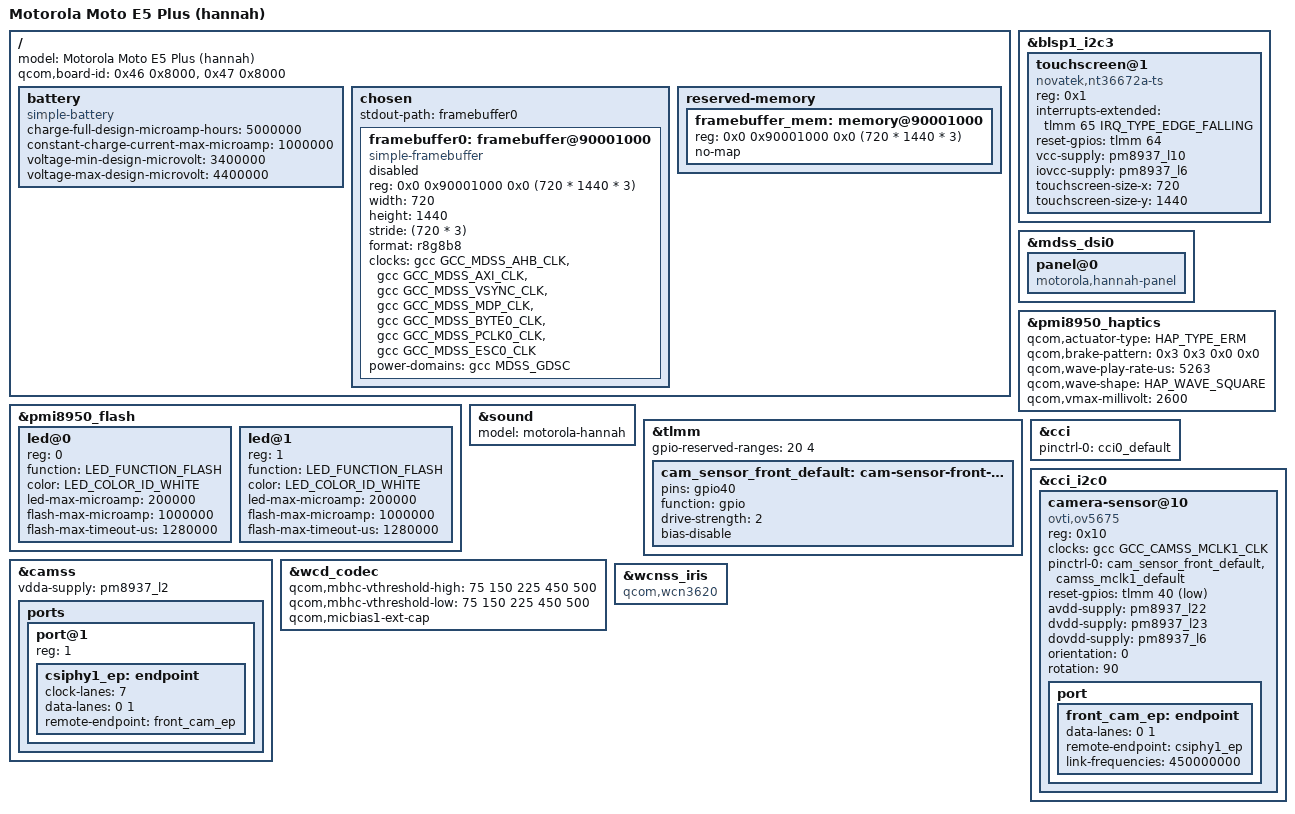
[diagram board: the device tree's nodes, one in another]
// SPDX-License-Identifier: BSD-3-Clause
/*
 * Copyright (c) 2025, Barnabas Czeman
 */

#include "msm89x7-motorola-common.dtsi"

/ {
	model = "Motorola Moto E5 Plus (hannah)";
	qcom,board-id = <0x46 0x8000>,
			<0x47 0x8000>;

	battery: battery {
		compatible = "simple-battery";

		charge-full-design-microamp-hours = <5000000>;
		constant-charge-current-max-microamp = <1000000>;
		voltage-min-design-microvolt = <3400000>;
		voltage-max-design-microvolt = <4400000>;
	};

	chosen {
		#address-cells = <2>;
		#size-cells = <2>;
		ranges;

		stdout-path = "framebuffer0";

		framebuffer0: framebuffer@90001000 {
			compatible = "simple-framebuffer";
			reg = <0x0 0x90001000 0x0 (720 * 1440 * 3)>;
			width = <720>;
			height = <1440>;
			stride = <(720 * 3)>;
			format = "r8g8b8";

			clocks = <&gcc GCC_MDSS_AHB_CLK>,
				 <&gcc GCC_MDSS_AXI_CLK>,
				 <&gcc GCC_MDSS_VSYNC_CLK>,
				 <&gcc GCC_MDSS_MDP_CLK>,
				 <&gcc GCC_MDSS_BYTE0_CLK>,
				 <&gcc GCC_MDSS_PCLK0_CLK>,
				 <&gcc GCC_MDSS_ESC0_CLK>;
			power-domains = <&gcc MDSS_GDSC>;
			status = "disabled";
		};
	};

	reserved-memory {
		framebuffer_mem: memory@90001000 {
			reg = <0x0 0x90001000 0x0 (720 * 1440 * 3)>;
			no-map;
		};
	};
};

&blsp1_i2c3 {
	status = "okay";

	touchscreen@1 {
		compatible = "novatek,nt36672a-ts";
		reg = <0x1>;
		interrupts-extended = <&tlmm 65 IRQ_TYPE_EDGE_FALLING>;
		reset-gpios = <&tlmm 64 GPIO_ACTIVE_HIGH>;
		vcc-supply = <&pm8937_l10>;
		iovcc-supply = <&pm8937_l6>;
		touchscreen-size-x = <720>;
		touchscreen-size-y = <1440>;
	};
};

&mdss_dsi0 {
	panel@0 {
		compatible = "motorola,hannah-panel";
	};
};

&pmi8950_flash {
	#address-cells = <1>;
	#size-cells = <0>;
	status = "okay";

	led@0 {
		reg = <0>;
		function = LED_FUNCTION_FLASH;
		color = <LED_COLOR_ID_WHITE>;
		led-max-microamp = <200000>;
		flash-max-microamp = <1000000>;
		flash-max-timeout-us = <1280000>;
	};

	led@1 {
		reg = <1>;
		function = LED_FUNCTION_FLASH;
		color = <LED_COLOR_ID_WHITE>;
		led-max-microamp = <200000>;
		flash-max-microamp = <1000000>;
		flash-max-timeout-us = <1280000>;
	};
};

&pmi8950_haptics {
	qcom,actuator-type = <HAP_TYPE_ERM>;
	qcom,brake-pattern = <0x3 0x3 0x0 0x0>;
	qcom,wave-play-rate-us = <5263>;
	qcom,wave-shape = <HAP_WAVE_SQUARE>;
	qcom,vmax-millivolt = <2600>;

	status = "okay";
};

&sound {
	model = "motorola-hannah";
};

&tlmm {
	gpio-reserved-ranges = <20 4>;

	cam_sensor_front_default: cam-sensor-front-default-state {
		pins = "gpio40";
		function = "gpio";
		drive-strength = <2>;
		bias-disable;
	};
};

&camss {
	vdda-supply = <&pm8937_l2>;
	status = "okay";

	ports {
		port@1 {
			reg = <1>;

			csiphy1_ep: endpoint {
				clock-lanes = <7>;
				data-lanes = <0 1>;
				remote-endpoint = <&front_cam_ep>;
			};
		};
	};
};

&cci {
	pinctrl-0 = <&cci0_default>;
	pinctrl-names = "default";

	status = "okay";
};

&cci_i2c0 {
	camera-sensor@10 {
		compatible = "ovti,ov5675";

		reg = <0x10>;

		clocks = <&gcc GCC_CAMSS_MCLK1_CLK>;

		pinctrl-0 = <&cam_sensor_front_default>, <&camss_mclk1_default>;
		pinctrl-names = "default";

		reset-gpios = <&tlmm 40 GPIO_ACTIVE_LOW>;

		avdd-supply= <&pm8937_l22>;
		dvdd-supply = <&pm8937_l23>;
		dovdd-supply = <&pm8937_l6>;
		orientation = <0>;
		rotation = <90>;

		port {
			front_cam_ep: endpoint {
				data-lanes = <0 1>;
				remote-endpoint = <&csiphy1_ep>;
				link-frequencies = /bits/ 64 <450000000>;
			};
		};
	};
};

&wcd_codec {
	qcom,mbhc-vthreshold-high = <75 150 225 450 500>;
	qcom,mbhc-vthreshold-low = <75 150 225 450 500>;
	qcom,micbias1-ext-cap;
};

&wcnss_iris {
	compatible = "qcom,wcn3620";
};
